# AT90PWM1 device description
Architecture: AVR8; Family: megaAVR
Registers are 8-bit, access not given, no defined reset value unless marked. A register's access mark holds for its fields unless they carry their own. Offsets are from the block's base; [hi:lo] are bit positions; {n}, {i} and the like mark numbered series; 'fields as' and 'values as' point back to an identical list.

## PORTB — I/O Port
Instances: PORTB 0x00
0x23 PINB — Port B Input Pins
0x24 DDRB — Port B Data Direction Register
0x25 PORTB — Port B Data Register

## PORTD — I/O Port
Instances: PORTD 0x00
0x29 PIND — Port D Input Pins
0x2A DDRD — Port D Data Direction Register
0x2B PORTD — Port D Data Register

## PORTE — I/O Port
Instances: PORTE 0x00
0x2C PINE bits used 2:0 — Port E Input Pins
0x2D DDRE bits used 2:0 — Port E Data Direction Register
0x2E PORTE bits used 2:0 — Port E Data Register

## BOOT_LOAD — Bootloader
Instances: BOOT_LOAD 0x00
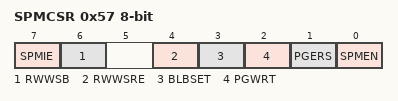
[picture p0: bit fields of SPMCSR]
0x57 SPMCSR — Store Program Memory Control Register
  [7] SPMIE — SPM Interrupt Enable
  [6] RWWSB — Read While Write Section Busy
  [4] RWWSRE — Read While Write section read enable
  [3] BLBSET — Boot Lock Bit Set
  [2] PGWRT — Page Write
  [1] PGERS — Page Erase
  [0] SPMEN — Store Program Memory Enable

## PSC0 — Power Stage Controller
Instances: PSC0 0x00
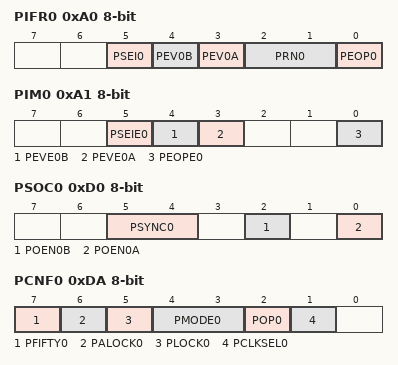
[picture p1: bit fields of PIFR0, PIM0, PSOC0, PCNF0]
0xA0 PIFR0 — PSC0 Interrupt Flag Register
  [5] PSEI0 — PSC 0 Synchro Error Interrupt
  [4] PEV0B — External Event B Interrupt
  [3] PEV0A — External Event A Interrupt
  [2:1] PRN0 — Ramp Number
    {v}={v+1} (v=0..3)
  [0] PEOP0 — End of PSC0 Interrupt
0xA1 PIM0 — PSC0 Interrupt Mask Register
  [5] PSEIE0 — PSC 0 Synchro Error Interrupt Enable
  [4] PEVE0B — External Event B Interrupt Enable
  [3] PEVE0A — External Event A Interrupt Enable
  [0] PEOPE0 — End of Cycle Interrupt Enable
0xD0 PSOC0 — PSC0 Synchro and Output Configuration
  [5:4] PSYNC0 — Synchronization Out for ADC Selection
    0=Send signal on leading edge of PSCOUTn0; 1=Send signal on trailing edge of PSCOUTn0; 2=Send signal on leading edge of PSCOUTn1; 3=Send signal on trailing edge of PSCOUTn1
  [2] POEN0B — PSCOUT01 Output Enable
  [0] POEN0A — PSCOUT00 Output Enable
0xD2 OCR0SA 16-bit bits used 11:0 — Output Compare SA Register
0xD4 OCR0RA 16-bit bits used 11:0 — Output Compare RA Register
0xD6 OCR0SB 16-bit bits used 11:0 — Output Compare SB Register
0xD8 OCR0RB 16-bit — Output Compare RB Register
0xDA PCNF0 — PSC 0 Configuration Register
  [7] PFIFTY0 — PSC 0 Fifty
  [6] PALOCK0 — PSC 0 Autolock
  [5] PLOCK0 — PSC 0 Lock
  [4:3] PMODE0 — PSC 0 Mode
    0=One Ramp Mode; 1=Two Ramp Mode; 2=Four Ramp Mode; 3=Center Aligned Mode
  [2] POP0 — PSC 0 Output Polarity
  [1] PCLKSEL0 — PSC 0 Input Clock Select
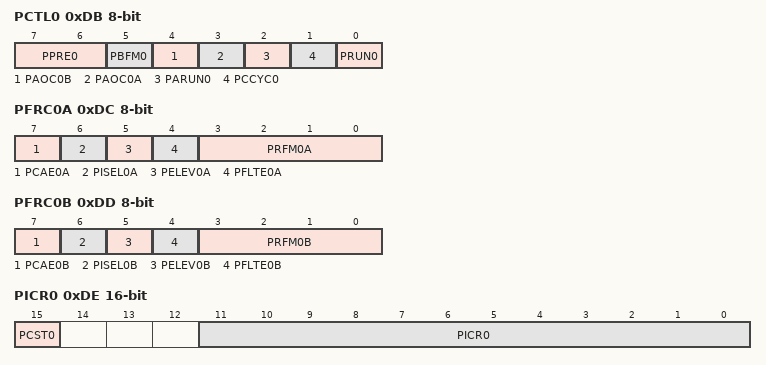
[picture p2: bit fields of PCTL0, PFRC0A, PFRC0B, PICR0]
0xDB PCTL0 — PSC 0 Control Register
  [7:6] PPRE0 — PSC 0 Prescaler Selects
    0=No divider on PSC input clock; 1=Divide the PSC input clock by 4; 2=Divide the PSC input clock by 16; 3=Divide the PSC input clock by 64
  [5] PBFM0 — PSC 0 Balance Flank Width Modulation
  [4] PAOC0B — PSC 0 Asynchronous Output Control B
  [3] PAOC0A — PSC 0 Asynchronous Output Control A
  [2] PARUN0 — PSC0 Auto Run
  [1] PCCYC0 — PSC0 Complete Cycle
  [0] PRUN0 — PSC 0 Run
0xDC PFRC0A — PSC 0 Input A Control
  [7] PCAE0A — PSC 0 Capture Enable Input Part A
  [6] PISEL0A — PSC 0 Input Select for Part A
  [5] PELEV0A — PSC 0 Edge Level Selector on Input Part A
  [4] PFLTE0A — PSC 0 Filter Enable on Input Part A
  [3:0] PRFM0A — PSC 0 Retrigger and Fault Mode for Part A
    0=No action, PSC Input is ignored; 1=Stop signal, Jump to Opposite Dead-Time and Wait; 2=Stop signal, Execute Opposite Dead-Time and Wait; 3=Stop signal, Execute Opposite while Fault active; 4=Deactivate outputs without changing timing; 5=Stop signal and Insert Dead-Time; 6=Stop signal, Jump to Opposite Dead-Time and Wait; 7=Halt PSC and Wait for Software Action; 8=Edge Retrigger PSC; 9=Fixed Frequency Edge Retrigger PSC; 14=Fixed Frequency Edge Retrigger PSC and Disactivate Output
0xDD PFRC0B — PSC 0 Input B Control
  [7] PCAE0B — PSC 0 Capture Enable Input Part B
  [6] PISEL0B — PSC 0 Input Select for Part B
  [5] PELEV0B — PSC 0 Edge Level Selector on Input Part B
  [4] PFLTE0B — PSC 0 Filter Enable on Input Part B
  [3:0] PRFM0B — PSC 0 Retrigger and Fault Mode for Part B
    values as PFRC0A.PRFM0A
0xDE PICR0 16-bit — PSC 0 Input Capture Register
  [15] PCST0 — PSC 0 Capture Software Trig bit
  [11:0] PICR0 — PSC 0 Capture Register
